AUTOSAR XML (schema 314)
package /ComponentType
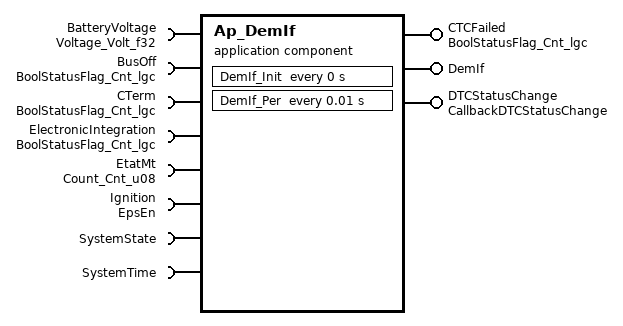
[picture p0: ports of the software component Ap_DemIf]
  application software component type Ap_DemIf
    provide port CTCFailed: unqueued-sender-com-spec{data-element=Cnt_lgc, can-invalidate=false, init-value=D_FALSE_CNT_LGC}, provided-interface=BoolStatusFlag_Cnt_lgc
    provide port DemIf: provided-interface=DemIf
      provided-com-specs:
        operation=DemShutdown, queue-length=1
        operation=RestartDem, queue-length=1
        operation=SetEventStatus, queue-length=1
        operation=SetOperationCycleState, queue-length=1
        operation=VehSpdControl, queue-length=1
    provide port DTCStatusChange: server-com-spec{operation=DTCStatusChanged, queue-length=1}, provided-interface=CallbackDTCStatusChange
    8 x require port:
      BatteryVoltage: unqueued-receiver-com-spec{data-element=Volt_f32, init-value=D_ZERO_ULS_F32}, required-interface=Voltage_Volt_f32
      BusOff: unqueued-receiver-com-spec{data-element=Cnt_lgc, init-value=D_FALSE_CNT_LGC}, required-interface=BoolStatusFlag_Cnt_lgc
      CTerm: unqueued-receiver-com-spec{data-element=Cnt_lgc, init-value=D_FALSE_CNT_LGC}, required-interface=BoolStatusFlag_Cnt_lgc
      ElectronicIntegration: unqueued-receiver-com-spec{data-element=Cnt_lgc, init-value=D_FALSE_CNT_LGC}, required-interface=BoolStatusFlag_Cnt_lgc
      EtatMt: unqueued-receiver-com-spec{data-element=Cnt_u08, init-value=D_ZERO_CNT_U8}, required-interface=Count_Cnt_u08
      Ignition: client-com-spec=OP_GET, required-interface=EpsEn
      SystemState: required-interface=SystemState
      SystemTime: required-interface=SystemTime
        required-com-specs:
          DtrmnElapsedTime_mS_u16
          DtrmnElapsedTime_mS_u32
          DtrmnElapsedTime_uS_u16
          DtrmnElapsedTime_uS_u32
          GetSystemTime_mS_u32
          GetSystemTime_uS_u32
  internal behavior Ap_DemIf_InternalBehavior: component=Ap_DemIf
    operation invoked event OIT_DemIf_DemShutdown_DemIf_DemShutdown: start-on-event=DemIf_DemShutdown, operation=DemIf.DemShutdown
    operation invoked event OIT_DemIf_DTCStatusChanged_DTCStatusChange_DTCStatusChanged: start-on-event=DemIf_DTCStatusChanged, operation=DTCStatusChange.DTCStatusChanged
    timing event DemIf_InitEvent: start-on-event=DemIf_Init, period=0
    timing event TMT_DemIf_Per: start-on-event=DemIf_Per, period=0.01
    4 x operation invoked event:
      OIT_DemIf_RestartDem_DemIf_RestartDem: start-on-event=DemIf_RestartDem, operation=DemIf.RestartDem
      OIT_DemIf_SetEventStatus_DemIf_SetEventStatus: start-on-event=DemIf_SetEventStatus, operation=DemIf.SetEventStatus
      OIT_DemIf_SetOperationCycleState_DemIf_SetOperationCycleState: start-on-event=DemIf_SetOperationCycleState, operation=DemIf.SetOperationCycleState
      OIT_DemIf_VehSpdControl_DemIf_VehSpdControl: start-on-event=DemIf_VehSpdControl, operation=DemIf.VehSpdControl
    port-api-options:
      enable-take-address=false, indirect-api=false, port=BatteryVoltage
      enable-take-address=false, indirect-api=false, port=BusOff
      enable-take-address=false, indirect-api=false, port=CTCFailed
      enable-take-address=false, indirect-api=false, port=CTerm
      enable-take-address=false, indirect-api=false, port=DemIf
      enable-take-address=false, indirect-api=false, port=DTCStatusChange
      enable-take-address=false, indirect-api=false, port=ElectronicIntegration
      enable-take-address=false, indirect-api=false, port=EtatMt
      enable-take-address=false, indirect-api=false, port=Ignition
      enable-take-address=false, indirect-api=false, port=SystemState
      enable-take-address=false, indirect-api=false, port=SystemTime
    8 x runnable:
      DemIf_DemShutdown: can-be-invoked-concurrently=true
      DemIf_DTCStatusChanged
        data send point SEND_CTCFailed_Cnt_lgc: data-element=CTCFailed.Cnt_lgc
      DemIf_Init
        sync call SC_SystemTime_GetSystemTime_mS_u32: operation=SystemTime.GetSystemTime_mS_u32, timeout=0
      DemIf_Per
        5 x data read access:
          READ_BatteryVoltage_Volt_f32: data-element=BatteryVoltage.Volt_f32
          READ_BusOff_Cnt_lgc: data-element=BusOff.Cnt_lgc
          READ_CTerm_Cnt_lgc: data-element=CTerm.Cnt_lgc
          READ_ElectronicIntegration_Cnt_lgc: data-element=ElectronicIntegration.Cnt_lgc
          READ_EtatMt_Cnt_u08: data-element=EtatMt.Cnt_u08
        sync call SC_Ignition_OP_GET: operation=Ignition.OP_GET, timeout=0
        sync call SC_SystemTime_DtrmnElapsedTime_mS_u16: operation=SystemTime.DtrmnElapsedTime_mS_u16, timeout=0
        sync call SC_SystemTime_GetSystemTime_mS_u32: operation=SystemTime.GetSystemTime_mS_u32, timeout=0
      DemIf_RestartDem: can-be-invoked-concurrently=true
      DemIf_SetEventStatus: can-be-invoked-concurrently=true
      DemIf_SetOperationCycleState: can-be-invoked-concurrently=true
      DemIf_VehSpdControl
  swc implementation Ap_DemIf_Implementation: behavior=Ap_DemIf_InternalBehavior
    code-descriptors:
      code Code: type=SRC
